# nrf54lm20a_enga_application register map
Vendor: Nordic Semiconductor; Series: nrf54l; File version: 1
CPU: CM33 r0p4, little endian, MPU, FPU, 3 interrupt priority bits, 270 interrupts, 4 SAU regions
Registers are 32-bit, read-write, reset 0x0 unless marked. A register's access mark holds for its fields unless they carry their own. Offsets are from the block's base; [hi:lo] are bit positions; lines under a group give offsets from that group; {n}, {i} and the like mark numbered series; 'fields as' and 'values as' point back to an identical list.

## GLOBAL_TDM_NS — Time division multiplexed audio interface 0
Base 0x400E8000
Same registers: GLOBAL_TDM_S 0x500E8000
0x00 TASKS_START wo — Starts continuous TDM transfer. Also starts MCK when this is enabled
  [0] TASKS_START
    1=Trigger task
0x04 TASKS_STOP wo — Stops TDM transfer after the completion of MAXCNT bytes. Triggering this task will cause the STOPPED event to be generated.
  [0] TASKS_STOP
    1=Trigger task
0x08 TASKS_ABORT wo — Abort TDM transfer without completing MAXCNT bytes. Triggering this task will cause the ABORTED event to be generated.
  [0] TASKS_ABORT
    1=Trigger task
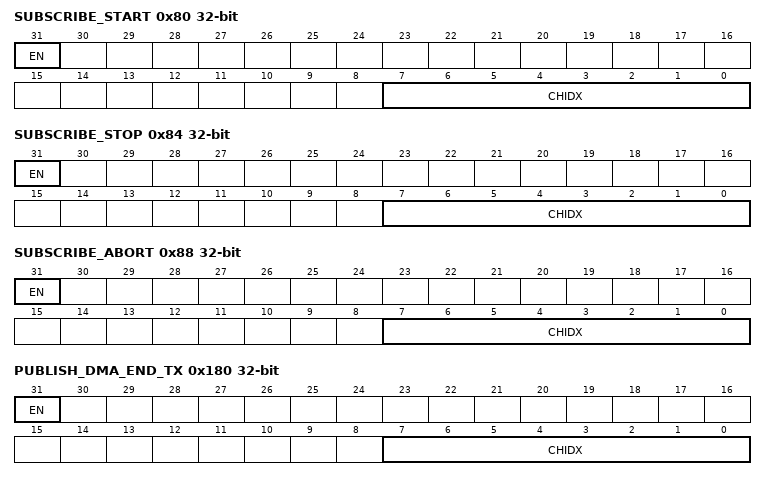
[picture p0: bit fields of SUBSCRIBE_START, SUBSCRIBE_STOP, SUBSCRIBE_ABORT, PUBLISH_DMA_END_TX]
0x80 SUBSCRIBE_START — Subscribe configuration for task START
  [31] EN
    0=Disabled (Disable subscription); 1=Enabled (Enable subscription)
  [7:0] CHIDX — DPPI channel that task START will subscribe to
0x84 SUBSCRIBE_STOP — Subscribe configuration for task STOP
  [31] EN
    values as SUBSCRIBE_START.EN
  [7:0] CHIDX — DPPI channel that task STOP will subscribe to
0x88 SUBSCRIBE_ABORT — Subscribe configuration for task ABORT
  [31] EN
    values as SUBSCRIBE_START.EN
  [7:0] CHIDX — DPPI channel that task ABORT will subscribe to
0x100 EVENTS_DMA_END_TX — End of transmission Equivalent to eventDmaEndTx
  [0] EVENTS_DMA_END_TX
    0=NotGenerated (Event not generated); 1=Generated (Event generated)
0x104 EVENTS_RXPTRUPD — The RXD.PTR register has been copied to internal double-buffers. When TDM is started and RX is enabled, this event will be generated for every RXTXD.MAXCNT bytes received on the SDIN pin. Equivalent to eventDmaReadyRx.
  [0] EVENTS_RXPTRUPD
    values as EVENTS_DMA_END_TX.EVENTS_DMA_END_TX
0x108 EVENTS_STOPPED — Transfer stopped.
  [0] EVENTS_STOPPED
    values as EVENTS_DMA_END_TX.EVENTS_DMA_END_TX
0x10C EVENTS_ABORTED — Transfer aborted.
  [0] EVENTS_ABORTED
    values as EVENTS_DMA_END_TX.EVENTS_DMA_END_TX
0x110 EVENTS_ERROR_TX — DMA read from memory failed. Equivalent to eventUnderflowTx
  [0] EVENTS_ERROR_TX
    values as EVENTS_DMA_END_TX.EVENTS_DMA_END_TX
0x114 EVENTS_ERROR_RX — DMA write to memory failed. Equivalent to eventOverflowRx
  [0] EVENTS_ERROR_RX
    values as EVENTS_DMA_END_TX.EVENTS_DMA_END_TX
0x118 EVENTS_TXPTRUPD — The TDX.PTR register has been copied to internal double-buffers. When TDM is started and TX is enabled, this event will be generated for every RXTXD.MAXCNT bytes that are sent on the SDOUT pin. Equivalent to eventDmaReadyTx.
  [0] EVENTS_TXPTRUPD
    values as EVENTS_DMA_END_TX.EVENTS_DMA_END_TX
0x11C EVENTS_DMA_END_RX — End of transmission Equivalent to eventDmaEndRx
  [0] EVENTS_DMA_END_RX
    values as EVENTS_DMA_END_TX.EVENTS_DMA_END_TX
0x120 EVENTS_MAXCNT — Generated on the active edge of FSYNC, after both RX and TX DMA transfers have completed
  [0] EVENTS_MAXCNT
    values as EVENTS_DMA_END_TX.EVENTS_DMA_END_TX
0x124 EVENTS_BUSERROR_RX — This event is generated if an error occurs during the bus transfer. This event is generated on an AHB / AXI error response.
  [0] EVENTS_BUSERROR_RX
    values as EVENTS_DMA_END_TX.EVENTS_DMA_END_TX
0x128 EVENTS_BUSERROR_TX — This event is generated if an error occurs during the bus transfer. This event is generated on an AHB / AXI error response.
  [0] EVENTS_BUSERROR_TX
    values as EVENTS_DMA_END_TX.EVENTS_DMA_END_TX
0x180 PUBLISH_DMA_END_TX — Publish configuration for event DMA_END_TX
  [31] EN
    0=Disabled (Disable publishing); 1=Enabled (Enable publishing)
  [7:0] CHIDX — DPPI channel that event DMA_END_TX will publish to
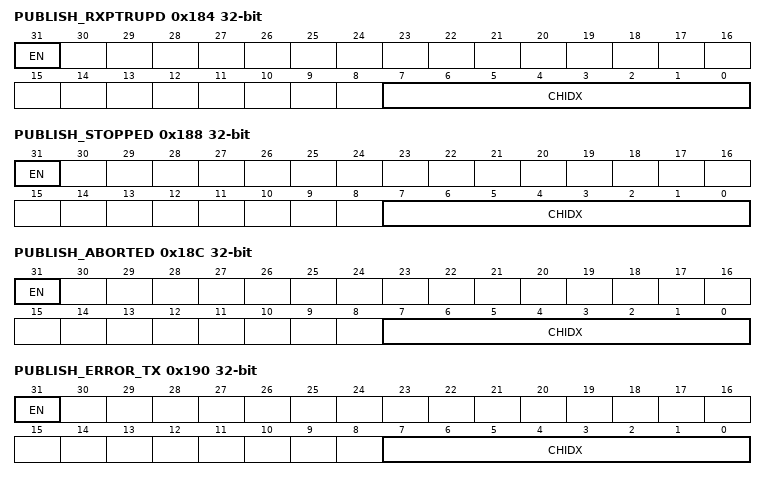
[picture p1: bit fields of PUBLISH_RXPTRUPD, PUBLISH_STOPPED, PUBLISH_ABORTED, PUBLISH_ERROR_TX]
0x184 PUBLISH_RXPTRUPD — Publish configuration for event RXPTRUPD
  [31] EN
    values as PUBLISH_DMA_END_TX.EN
  [7:0] CHIDX — DPPI channel that event RXPTRUPD will publish to
0x188 PUBLISH_STOPPED — Publish configuration for event STOPPED
  [31] EN
    values as PUBLISH_DMA_END_TX.EN
  [7:0] CHIDX — DPPI channel that event STOPPED will publish to
0x18C PUBLISH_ABORTED — Publish configuration for event ABORTED
  [31] EN
    values as PUBLISH_DMA_END_TX.EN
  [7:0] CHIDX — DPPI channel that event ABORTED will publish to
0x190 PUBLISH_ERROR_TX — Publish configuration for event ERROR_TX
  [31] EN
    values as PUBLISH_DMA_END_TX.EN
  [7:0] CHIDX — DPPI channel that event ERROR_TX will publish to
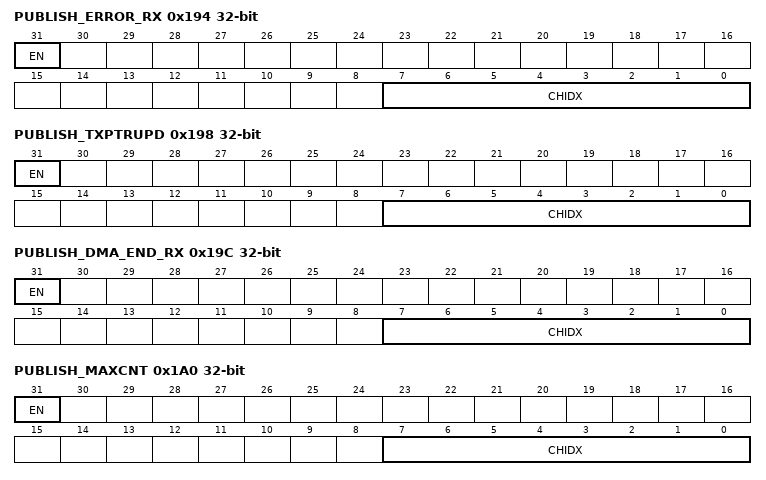
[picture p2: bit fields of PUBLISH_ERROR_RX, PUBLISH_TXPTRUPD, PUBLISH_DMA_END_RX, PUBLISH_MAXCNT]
0x194 PUBLISH_ERROR_RX — Publish configuration for event ERROR_RX
  [31] EN
    values as PUBLISH_DMA_END_TX.EN
  [7:0] CHIDX — DPPI channel that event ERROR_RX will publish to
0x198 PUBLISH_TXPTRUPD — Publish configuration for event TXPTRUPD
  [31] EN
    values as PUBLISH_DMA_END_TX.EN
  [7:0] CHIDX — DPPI channel that event TXPTRUPD will publish to
0x19C PUBLISH_DMA_END_RX — Publish configuration for event DMA_END_RX
  [31] EN
    values as PUBLISH_DMA_END_TX.EN
  [7:0] CHIDX — DPPI channel that event DMA_END_RX will publish to
0x1A0 PUBLISH_MAXCNT — Publish configuration for event MAXCNT
  [31] EN
    values as PUBLISH_DMA_END_TX.EN
  [7:0] CHIDX — DPPI channel that event MAXCNT will publish to
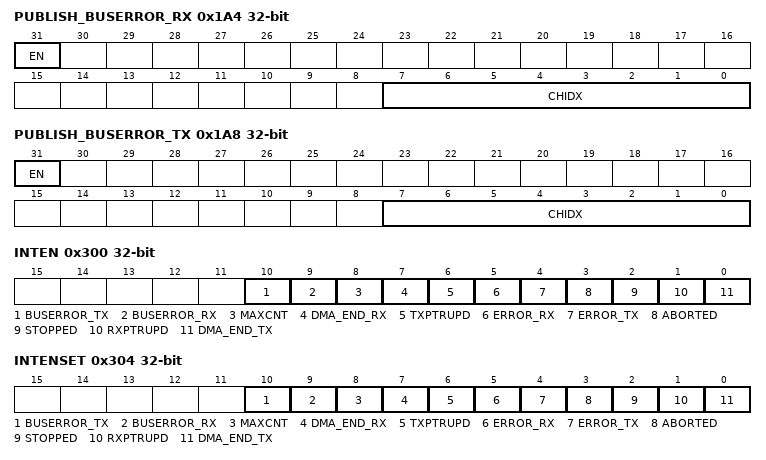
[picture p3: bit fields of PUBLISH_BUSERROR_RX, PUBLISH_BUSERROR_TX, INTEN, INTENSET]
0x1A4 PUBLISH_BUSERROR_RX — Publish configuration for event BUSERROR_RX
  [31] EN
    values as PUBLISH_DMA_END_TX.EN
  [7:0] CHIDX — DPPI channel that event BUSERROR_RX will publish to
0x1A8 PUBLISH_BUSERROR_TX — Publish configuration for event BUSERROR_TX
  [31] EN
    values as PUBLISH_DMA_END_TX.EN
  [7:0] CHIDX — DPPI channel that event BUSERROR_TX will publish to
0x300 INTEN — Enable or disable interrupt
  [all] fields
    0=Disabled; 1=Enabled
  [10] BUSERROR_TX — Enable or disable interrupt for event BUSERROR_TX
  [9] BUSERROR_RX — Enable or disable interrupt for event BUSERROR_RX
  [8] MAXCNT — Enable or disable interrupt for event MAXCNT
  [7] DMA_END_RX — Enable or disable interrupt for event DMA_END_RX
  [6] TXPTRUPD — Enable or disable interrupt for event TXPTRUPD
  [5] ERROR_RX — Enable or disable interrupt for event ERROR_RX
  [4] ERROR_TX — Enable or disable interrupt for event ERROR_TX
  [3] ABORTED — Enable or disable interrupt for event ABORTED
  [2] STOPPED — Enable or disable interrupt for event STOPPED
  [1] RXPTRUPD — Enable or disable interrupt for event RXPTRUPD
  [0] DMA_END_TX — Enable or disable interrupt for event DMA_END_TX
0x304 INTENSET — Enable interrupt
  [all] fields
    on read: 0=Disabled (Read: Disabled); 1=Enabled (Read: Enabled) | on write: 1=Set (Enable)
  [10] BUSERROR_TX — Write '1' to enable interrupt for event BUSERROR_TX
  [9] BUSERROR_RX — Write '1' to enable interrupt for event BUSERROR_RX
  [8] MAXCNT — Write '1' to enable interrupt for event MAXCNT
  [7] DMA_END_RX — Write '1' to enable interrupt for event DMA_END_RX
  [6] TXPTRUPD — Write '1' to enable interrupt for event TXPTRUPD
  [5] ERROR_RX — Write '1' to enable interrupt for event ERROR_RX
  [4] ERROR_TX — Write '1' to enable interrupt for event ERROR_TX
  [3] ABORTED — Write '1' to enable interrupt for event ABORTED
  [2] STOPPED — Write '1' to enable interrupt for event STOPPED
  [1] RXPTRUPD — Write '1' to enable interrupt for event RXPTRUPD
  [0] DMA_END_TX — Write '1' to enable interrupt for event DMA_END_TX
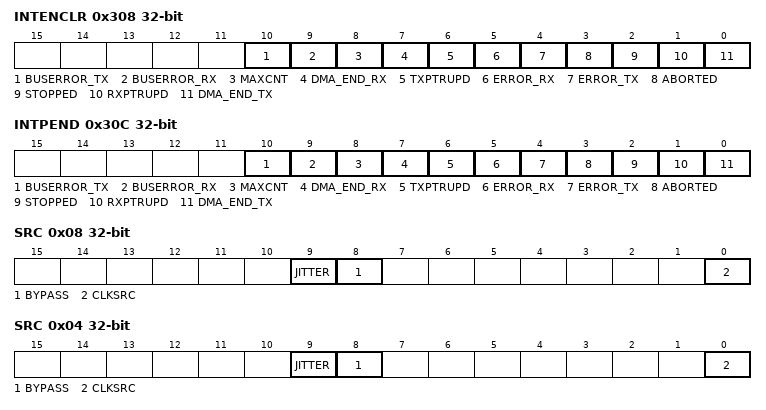
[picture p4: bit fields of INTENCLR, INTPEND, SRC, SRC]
0x308 INTENCLR — Disable interrupt
  [all] fields
    on read: 0=Disabled (Read: Disabled); 1=Enabled (Read: Enabled) | on write: 1=Clear (Disable)
  [10] BUSERROR_TX — Write '1' to disable interrupt for event BUSERROR_TX
  [9] BUSERROR_RX — Write '1' to disable interrupt for event BUSERROR_RX
  [8] MAXCNT — Write '1' to disable interrupt for event MAXCNT
  [7] DMA_END_RX — Write '1' to disable interrupt for event DMA_END_RX
  [6] TXPTRUPD — Write '1' to disable interrupt for event TXPTRUPD
  [5] ERROR_RX — Write '1' to disable interrupt for event ERROR_RX
  [4] ERROR_TX — Write '1' to disable interrupt for event ERROR_TX
  [3] ABORTED — Write '1' to disable interrupt for event ABORTED
  [2] STOPPED — Write '1' to disable interrupt for event STOPPED
  [1] RXPTRUPD — Write '1' to disable interrupt for event RXPTRUPD
  [0] DMA_END_TX — Write '1' to disable interrupt for event DMA_END_TX
0x30C INTPEND ro — Pending interrupts
  [all] fields
    on read: 0=NotPending (Read: Not pending); 1=Pending (Read: Pending)
  [10] BUSERROR_TX — Read pending status of interrupt for event BUSERROR_TX
  [9] BUSERROR_RX — Read pending status of interrupt for event BUSERROR_RX
  [8] MAXCNT — Read pending status of interrupt for event MAXCNT
  [7] DMA_END_RX — Read pending status of interrupt for event DMA_END_RX
  [6] TXPTRUPD — Read pending status of interrupt for event TXPTRUPD
  [5] ERROR_RX — Read pending status of interrupt for event ERROR_RX
  [4] ERROR_TX — Read pending status of interrupt for event ERROR_TX
  [3] ABORTED — Read pending status of interrupt for event ABORTED
  [2] STOPPED — Read pending status of interrupt for event STOPPED
  [1] RXPTRUPD — Read pending status of interrupt for event RXPTRUPD
  [0] DMA_END_TX — Read pending status of interrupt for event DMA_END_TX
0x500 ENABLE — Enable TDM
  [0] ENABLE
    0=Disabled; 1=Enabled
0x504 CONFIG group — Configuration registers.
  0x00 MODE — Mode configuration
    [0] MODE
      0=Master mode. SCK and FSYNC are created internally and output on PSEL.SCK and PSEL.FSYNC.; 1=Slave mode. SCK and FSYNC are received on PSEL.SCK and PSEL.FSYNC.
  0x04 RXTXEN — Reception (RX) and transmission (TX) enable.
    [1:0] RXTXEN — Enable reception or transmission.
      0=Duplex (Enable both reception and transmission. Data will be written to the RXD.PTR address and data transmitted from the TXD.PTR address.); 1=Rx (Enable reception, disable transmission. Data will be written to the RXD.PTR address.); 2=Tx (Enable transmission, disable reception. Data will be transmitted from the TXD.PTR address.)
  0x08 MCK group — Unspecified
    0x00 EN — Master clock generator enable.
      [0] MCKEN
        0=Disabled (Master clock generator disabled.); 1=Enabled (Master clock generator enabled.)
    0x04 DIV — MCK divider.
      [31:0] DIV — MCK frequency configuration
        0x80000000=CKDIV2 (CK divided by 2); 0x50000000=CKDIV3 (CK divided by 3); 0x40000000=CKDIV4 (CK divided by 4); 0x30000000=CKDIV5 (CK divided by 5); 0x28000000=CKDIV6 (CK divided by 6); 0x20000000=CKDIV8 (CK divided by 8); 0x18000000=CKDIV10 (CK divided by 10); 0x16000000=CKDIV11 (CK divided by 11); 0x11000000=CKDIV15 (CK divided by 15); 0x10000000=CKDIV16 (CK divided by 16); 0xC000000=CKDIV21 (CK divided by 21); 0xB000000=CKDIV23 (CK divided by 23); 0x8800000=CKDIV30 (CK divided by 30); 0x8400000=CKDIV31 (CK divided by 31); 0x8000000=CKDIV32 (CK divided by 32); 0x6000000=CKDIV42 (CK divided by 42); 0x4100000=CKDIV63 (CK divided by 63); 0x20C0000=CKDIV125 (CK divided by 125)
    0x08 SRC — MCK clock source selection
      [9] JITTER — Enable jittering clock.
        0=Disable jitter; 1=Enable jitter
      [8] BYPASS — Bypass clock generator. MCK will be equal to source input. If bypass is enabled the MCKFREQ setting has no effect.
        0=Disable bypass; 1=Enable bypass
      [0] CLKSRC — Clock source selection
        0=PCLK (Peripheral clock (instantiation table shows the TDM PCLK frequency)); 0=PCLK32M (Deprecated enumerator - Legacy enumerator provided for backward compatibility); 1=ACLK (Audio PLL clock)
  0x14 SCK group — Unspecified
    0x00 DIV — SCK divider.
      [31:0] SCKDIV — SCK frequency configuration
        values as CONFIG.MCK.DIV.DIV
    0x04 SRC — SCK clock source selection
      [9] JITTER — Enable jittering clock.
        0=Disable jitter; 1=Enable jitter
      [8] BYPASS — Bypass clock generator. SCK will be equal to source input. If bypass is enabled the SCKFREQ setting has no effect.
        0=Disable bypass; 1=Enable bypass
      [0] CLKSRC — Clock source selection
        0=PCLK (Peripheral clock (instantiation table shows the TDM PCLK frequency)); 1=ACLK (Audio PLL clock)
    0x08 POLARITY — Set SCK Polarity.
      [0] SCKPOLARITY — Set the polarity of the active SCK edge.
        0=PosEdge (TX data is written to the SDOUT pin on the falling edge of SCK, ready to be received on the rising edge of SCK.); 1=NegEdge (TX data is written to the SDOUT pin on the rising edge of SCK, ready to be received on the falling edge of SCK.)
  0x20 SWIDTH reset 0x1 — Sample and word width configuration.
    [2:0] SWIDTH — Sample and word width
      0=8 bit sample in an 8-bit word; 1=16 bit sample in a 16-bit word; 2=24 bit sample in a 24-bit word; 3=32 bit sample in a 32-bit word; 4=8BitIn16 (8 bit sample in a 16-bit word.); 5=8BitIn32 (8 bit sample in a 32-bit word.); 6=16BitIn32 (16 bit sample in a 32-bit word.); 7=24BitIn32 (24 bit sample in a 32-bit word.)
  0x24 ALIGN — Alignment of sample within the audio data word.
    [0] ALIGN
      0=Left-aligned; 1=Right-aligned
  0x28 CHANNEL group — Unspecified
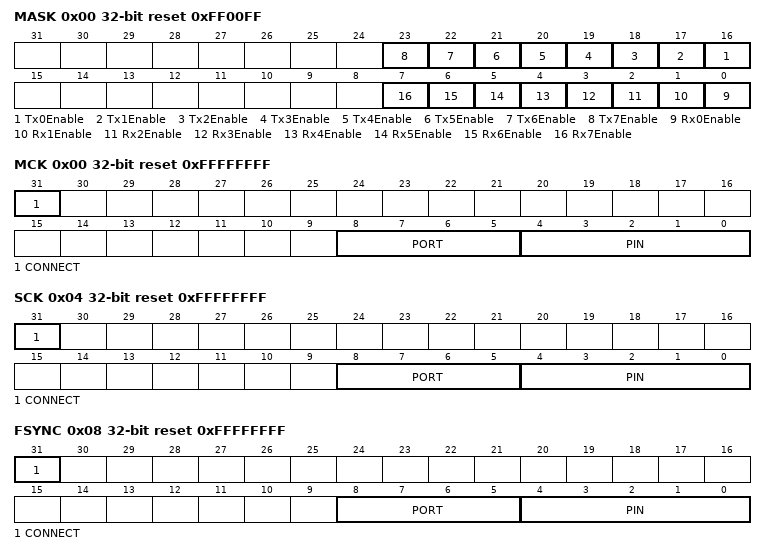
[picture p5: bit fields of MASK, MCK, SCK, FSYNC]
    0x00 MASK reset 0xFF00FF — Select which channels are to be used.
      [n+16] Tx{n}Enable (n=0..7)
        0=Disable Tx channel data; 1=Enable Tx channel data
      [n] Rx{n}Enable (n=0..7)
        0=Disable Rx channel data; 1=Enable Rx channel data
    0x04 NUM reset 0x1 — Select number of channels.
      [2:0] NUM
        0=Tdm1Ch (1-channel audio (mono).); 1=Tdm2Ch (2-channel audio (stereo).); {v}=Tdm{v+1}Ch ({v+1}-channel audio.) (v=2..7)
    0x08 DELAY reset 0x1 — Set channel delay.
      [1:0] DELAY — Configure number of inactive SCK periods from edge of FSYNC until start of first data bit.
        0=Delay0Ck (No delay. Used with I2S DSP/Aligned format.); 1=Delay1Ck (One clock pulse delay. Used with Original I2S format.); 2=Delay2Ck (Two clock pulses delay.)
  0x34 FSYNC group — Unspecified
    0x00 POLARITY — Set FSYNC Polarity.
      [0] POLARITY — Set the polarity of the active period of FSYNC.
        0=NegEdge (Frame starts at falling edge of FSYNC.); 1=PosEdge (Frame starts at rising edge of FSYNC.)
    0x04 DURATION reset 0x1 — Set FSYNC duration.
      [0] DURATION — Set the duration of the active period of FSYNC in Master mode.
        0=Sck (FSYNC is active for the duration of one SCK period); 1=Channel (FSYNC is active for the duration of channel)
  0x3C ORS — Over-read sample: Extra sample(s) to be transmitted after TXD.MAXCNT bytes have been transmitted.
    [31:0] ORS — Data to transmit after TXD.MAXCNT bytes have been transmitted.
0x570 PSEL group — Unspecified
  0x00 MCK reset 0xFFFFFFFF — Pin select for MCK signal
    [31] CONNECT — Connection
      1=Disconnected; 0=Connected
    [8:5] PORT — Port number
    [4:0] PIN — Pin number
  0x04 SCK reset 0xFFFFFFFF — Pin select for SCK signal
    fields as PSEL.MCK
  0x08 FSYNC reset 0xFFFFFFFF — Pin select for FSYNC signal
    fields as PSEL.MCK
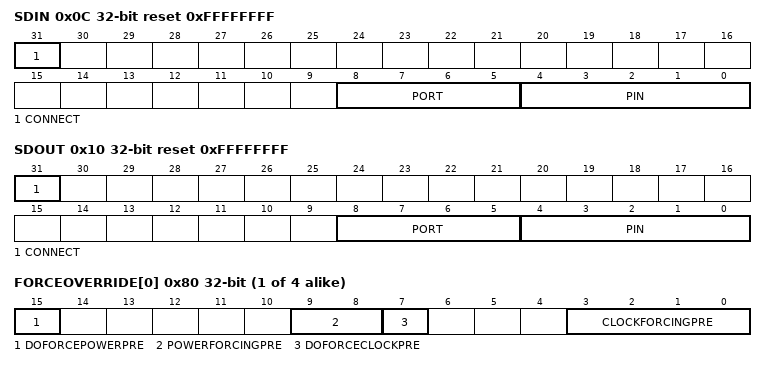
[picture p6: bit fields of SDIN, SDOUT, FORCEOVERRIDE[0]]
  0x0C SDIN reset 0xFFFFFFFF — Pin select for SDIN signal
    fields as PSEL.MCK
  0x10 SDOUT reset 0xFFFFFFFF — Pin select for SDOUT signal
    fields as PSEL.MCK
0x700 RXD group — Unspecified
  0x00 ENABLE — Register doesn't do anything. Can be written and read, but has no functionality attached.
    [0] ENABLE
      0=Disabled; 1=Enabled
  0x04 PTR reset 0x20000000 — RAM buffer start address
    [31:0] PTR — RAM buffer start address for this EasyDMA channel. This address is a word aligned Data RAM address.
  0x08 MAXCNT — Maximum number of bytes in channel buffer
    [15:0] MAXCNT
  0x0C AMOUNT ro — Number of bytes transferred in the last transaction, updated after the END event.
    [15:0] AMOUNT — Number of bytes transferred in the last transaction. In case of NACK error, includes the NACK'ed byte.
  0x10 CURRENTAMOUNT ro — Number of bytes transferred in the current transaction
    [15:0] AMOUNT — Number of bytes transferred in the current transaction. Continuously updated. Updated when data leaves the internal FIFO and is transferred to the destination.
  0x18 MODE reset 0x1 — Configure EasyDMA mode
    [1:0] LPOP — Enable low-power operation, or use low-latency
      0=Low-latency operation; 1=Low-power operation
  0x1C TERMINATEONBUSERROR — Terminate the transaction if a BUSERROR event is detected.
    [0] ENABLE
      0=Disabled; 1=Enabled
  0x20 BUSERRORADDRESS ro — Address of transaction that generated the last BUSERROR event.
    [31:0] ADDRESS
0x740 TXD group — Unspecified
  0x00 ENABLE — Register doesn't do anything. Can be written and read, but has no functionality attached.
    [0] ENABLE
      0=Disabled; 1=Enabled
  0x04 PTR reset 0x20000000 — RAM buffer start address
    fields as RXD.PTR
  0x08 MAXCNT — Maximum number of bytes in channel buffer
    [15:0] MAXCNT
  0x0C AMOUNT ro — Number of bytes transferred in the last transaction, updated after the END event.
    fields as RXD.AMOUNT
  0x10 CURRENTAMOUNT ro — Number of bytes transferred in the current transaction
    fields as RXD.CURRENTAMOUNT
  0x18 MODE reset 0x1 — Configure EasyDMA mode
    fields as RXD.MODE
  0x1C TERMINATEONBUSERROR — Terminate the transaction if a BUSERROR event is detected.
    [0] ENABLE
      0=Disabled; 1=Enabled
  0x20 BUSERRORADDRESS ro — Address of transaction that generated the last BUSERROR event.
    [31:0] ADDRESS
0xB00 PCGCS group — Unspecified
  0x00 TDM group — Unspecified
    {0x0+4k} PENALTY[{k}] (k=0..3) reset 0xFFFFFFFC — Description collection: Penalty level for power/clock pair n. When FULL_PCP_ZERO feature is not supported, PENALTY[0] address overlaps the PENALTY0 address and register description for PENALTY[0] is not valid.
      [1:0] PENALTY — Penalty level
    0x00 PENALTY0 (alternate view of PENALTY[*]) — Penalty level for power/clock pair 0. The register description is valid only when FULL_PCP_ZERO feature is not supported
      [1:0] PENALTY ro — Penalty level
    {0x80+4k} FORCEOVERRIDE[{k}] (k=0..3) — Description collection: Force override of power/clock pair n.
      [15] DOFORCEPOWERPRE, [9:8] POWERFORCINGPRE, [7] DOFORCECLOCKPRE, [3:0] CLOCKFORCINGPRE
  0x100 BRGMCK group — Unspecified
    {0x0+4k} PENALTY[{k}] (k=0..2) reset 0xFFFFFFFC — Description collection: Penalty level for power/clock pair n. When FULL_PCP_ZERO feature is not supported, PENALTY[0] address overlaps the PENALTY0 address and register description for PENALTY[0] is not valid.
      [1:0] PENALTY — Penalty level
    0x00 PENALTY0 (alternate view of PENALTY[*]) — Penalty level for power/clock pair 0. The register description is valid only when FULL_PCP_ZERO feature is not supported
      [1:0] PENALTY ro — Penalty level
    {0x80+4k} FORCEOVERRIDE[{k}] (k=0..2) — Description collection: Force override of power/clock pair n.
      fields as PCGCS.TDM.FORCEOVERRIDE[0]
  0x200 BRGSCK group — Unspecified
    {0x0+4k} PENALTY[{k}] (k=0..2) reset 0xFFFFFFFC — Description collection: Penalty level for power/clock pair n. When FULL_PCP_ZERO feature is not supported, PENALTY[0] address overlaps the PENALTY0 address and register description for PENALTY[0] is not valid.
      [1:0] PENALTY — Penalty level
    0x00 PENALTY0 (alternate view of PENALTY[*]) — Penalty level for power/clock pair 0. The register description is valid only when FULL_PCP_ZERO feature is not supported
      [1:0] PENALTY ro — Penalty level
    {0x80+4k} FORCEOVERRIDE[{k}] (k=0..2) — Description collection: Force override of power/clock pair n.
      fields as PCGCS.TDM.FORCEOVERRIDE[0]
  0x300 DMARX group — Unspecified
    {0x0+4k} PENALTY[{k}] (k=0..1) reset 0xFFFFFFFC — Description collection: Penalty level for power/clock pair n. When FULL_PCP_ZERO feature is not supported, PENALTY[0] address overlaps the PENALTY0 address and register description for PENALTY[0] is not valid.
      [1:0] PENALTY — Penalty level
    0x00 PENALTY0 (alternate view of PENALTY[*]) — Penalty level for power/clock pair 0. The register description is valid only when FULL_PCP_ZERO feature is not supported
      [1:0] PENALTY ro — Penalty level
    {0x80+4k} FORCEOVERRIDE[{k}] (k=0..1) — Description collection: Force override of power/clock pair n.
      fields as PCGCS.TDM.FORCEOVERRIDE[0]
  0x400 DMATX group — Unspecified
    {0x0+4k} PENALTY[{k}] (k=0..1) reset 0xFFFFFFFC — Description collection: Penalty level for power/clock pair n. When FULL_PCP_ZERO feature is not supported, PENALTY[0] address overlaps the PENALTY0 address and register description for PENALTY[0] is not valid.
      [1:0] PENALTY — Penalty level
    0x00 PENALTY0 (alternate view of PENALTY[*]) — Penalty level for power/clock pair 0. The register description is valid only when FULL_PCP_ZERO feature is not supported
      [1:0] PENALTY ro — Penalty level
    {0x80+4k} FORCEOVERRIDE[{k}] (k=0..1) — Description collection: Force override of power/clock pair n.
      fields as PCGCS.TDM.FORCEOVERRIDE[0]
